# ESP32S31_RADIO register map
Vendor: Espressif; Series: ESP32-S31; File version: 3.52
Registers are 32-bit, read-write, no defined reset value unless marked. A register's access mark holds for its fields unless they carry their own. Offsets are from the block's base; [hi:lo] are bit positions; {n}, {i} and the like mark numbered series.

## PHY_FREQUENCY_CHANNEL_ORACLE — Frequency-memory, hardware channel-switch, NRX and channel-bandwidth registers recovered from complete finite ROM/blob bodies. Names retain UNKNOWN where the instructions prove a field but not its electrical meaning. One physical word has one identity even when a bit has different mode-dependent roles.
Base 0x20100000
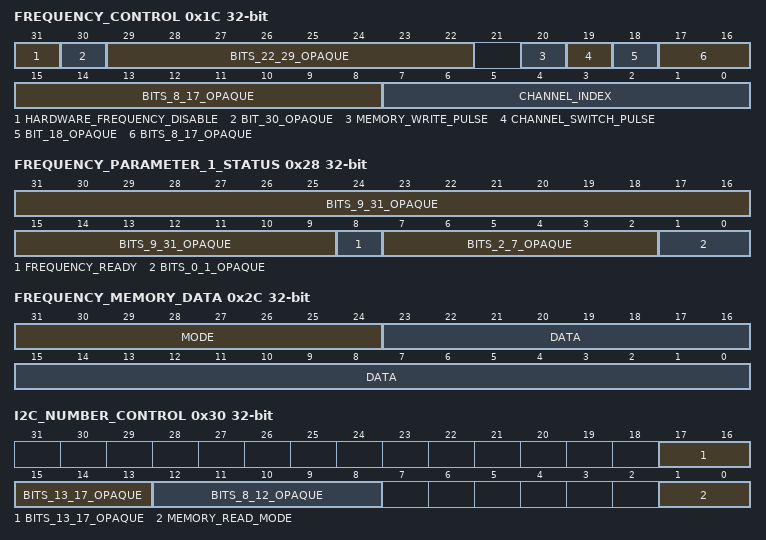
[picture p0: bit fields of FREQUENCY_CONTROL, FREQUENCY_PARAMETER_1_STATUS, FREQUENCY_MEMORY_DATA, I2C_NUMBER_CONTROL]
0x1C FREQUENCY_CONTROL — Project-assigned name. Shared frequency module control word. Bit 18 is both the high bit of an eleven-bit command-memory address and the reset/release bit pulsed by phy_freq_module_resetn.
  [31] HARDWARE_FREQUENCY_DISABLE — Project-assigned name. Complete phy_dis_hw_set_freq sets bit 31 before its two-microsecond delay; complete phy_en_hw_set_freq clears it.
  [30] BIT_30_OPAQUE — Opaque: meaning not established. Complete phy_freq_reg_init sets bit 30.
  [29:22] BITS_22_29_OPAQUE — Opaque: meaning not established. Complete phy_freq_reg_init replaces bits 29:22 with its two input nibbles; the electrical encoding is unknown.
  [20] MEMORY_WRITE_PULSE — Project-assigned name. Complete phy_freq_i2c_mem_write sets then clears bit 20 after publishing data.
  [19] CHANNEL_SWITCH_PULSE — Project-assigned name. Complete phy_freq_chan_en_sw sets bit 19, delays one microsecond, then clears it.
  [18] BIT_18_OPAQUE — Opaque: meaning not established. High address bit during frequency-memory writes; independently cleared then set by complete phy_freq_module_resetn.
  [17:8] BITS_8_17_OPAQUE — Opaque: meaning not established. Low ten bits of the eleven-bit address selected by phy_freq_i2c_mem_write.
  [7:0] CHANNEL_INDEX — Project-assigned name. Complete phy_freq_chan_en_sw replaces the low byte with the caller's frequency-table index.
0x20 FREQUENCY_MEMORY_READ_CONTROL — Project-assigned name. Complete phy_read_rf_freq_mem pulses bit 16 after publishing the address and read mode; all other bits remain preserved and unnamed.
  [16] READ_PULSE — Project-assigned name. Set and then cleared by complete phy_read_rf_freq_mem for one synchronous frequency-memory read transaction.
0x24 WORD_0024_OPAQUE wo — Opaque: meaning not established. Complete phy_freq_reg_init writes the full constant 0x19800249; no constituent electrical fields are public.
  [31:0] BITS_0_31_OPAQUE — Opaque: meaning not established.
0x28 FREQUENCY_PARAMETER_1_STATUS — Project-assigned name. Complete phy_freq_reg_init writes 0x25824e58; phy_bb_init replaces the low baseband-mode field, and the open channel state machine samples bit 8 for the evidenced ready edge.
  [31:9] BITS_9_31_OPAQUE — Opaque: meaning not established. Bits 31:9 of the complete initialization image.
  [8] FREQUENCY_READY ro — Project-assigned name. The complete channel parent samples bit 8 after the frequency-switch delay and branches on its asserted edge.
  [7:2] BITS_2_7_OPAQUE — Opaque: meaning not established. Bits 7:2 of the complete initialization image.
  [1:0] BITS_0_1_OPAQUE — Opaque: meaning not established. Complete phy_bb_init writes encoding two before calibration and zero after the initial channel setup.
0x2C FREQUENCY_MEMORY_DATA wo — Project-assigned name. Data/mode word published by complete phy_freq_i2c_mem_write.
  [31:24] MODE — Project-assigned name.
  [23:0] DATA — Project-assigned name.
0x30 I2C_NUMBER_CONTROL — Project-assigned name. First two five-bit PHY-I2C number addresses packed by complete phy_freq_i2c_num_addr.
  [17:13] BITS_13_17_OPAQUE — Opaque: meaning not established.
  [12:8] BITS_8_12_OPAQUE — Opaque: meaning not established.
  [1:0] MEMORY_READ_MODE — Project-assigned name. Complete phy_read_rf_freq_mem replaces only the low two bits with its read-mode argument.
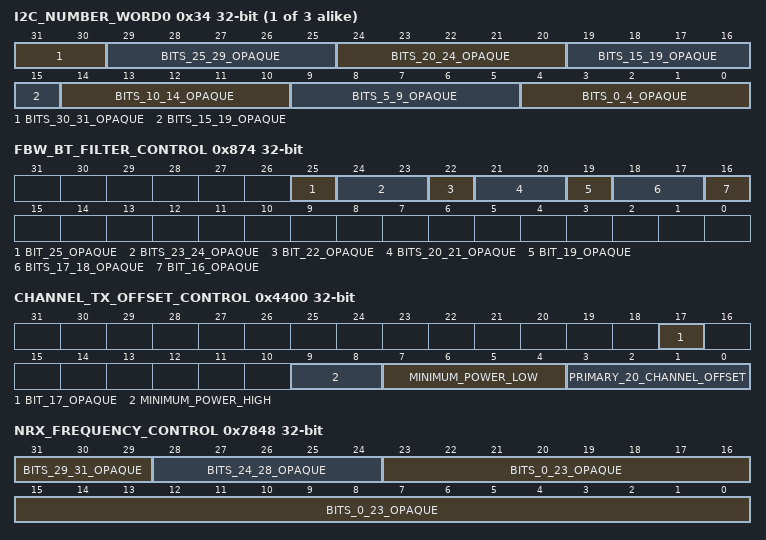
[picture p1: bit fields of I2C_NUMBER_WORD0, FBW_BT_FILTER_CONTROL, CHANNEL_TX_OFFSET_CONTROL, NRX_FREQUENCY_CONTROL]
{0x34+4i} I2C_NUMBER_WORD{i} (i=0..2) wo — Project-assigned name. Six consecutive five-bit PHY-I2C number addresses packed by complete phy_freq_num_get_data; unused slots are zero.
  [31:30] BITS_30_31_OPAQUE — Opaque: meaning not established. High two bits of the complete caller-prepared word; the recovered producer normally leaves them zero.
  [29:25] BITS_25_29_OPAQUE — Opaque: meaning not established.
  [24:20] BITS_20_24_OPAQUE — Opaque: meaning not established.
  [19:15] BITS_15_19_OPAQUE — Opaque: meaning not established.
  [14:10] BITS_10_14_OPAQUE — Opaque: meaning not established.
  [9:5] BITS_5_9_OPAQUE — Opaque: meaning not established.
  [4:0] BITS_0_4_OPAQUE — Opaque: meaning not established.
0x40 FREQUENCY_MEMORY_READ_RESULT ro — Project-assigned name. Complete phy_read_rf_freq_mem returns this full word after the read pulse; individual result fields are interpreted by the caller.
  [31:0] VALUE — Project-assigned name. Complete phy_read_rf_freq_mem returns this full read-only result to its caller.
0x874 FBW_BT_FILTER_CONTROL — Project-assigned name. Shared filter-bandwidth and Bluetooth-filter word independently updated by complete phy_wifi_fbw_sel and phy_bt_filter_reg.
  [25] BIT_25_OPAQUE — Opaque: meaning not established.
  [24:23] BITS_23_24_OPAQUE — Opaque: meaning not established.
  [22] BIT_22_OPAQUE — Opaque: meaning not established.
  [21:20] BITS_20_21_OPAQUE — Opaque: meaning not established.
  [19] BIT_19_OPAQUE — Opaque: meaning not established.
  [18:17] BITS_17_18_OPAQUE — Opaque: meaning not established.
  [16] BIT_16_OPAQUE — Opaque: meaning not established.
0x4400 CHANNEL_TX_OFFSET_CONTROL — Project-assigned name. Canonical multifunction PHY/MAC word. Complete phy_mac_tx_chan_offset and phy_bb_cbw_chan_cfg update the low channel-offset field; complete hal_set_tx_min_pwr updates bits 9:4 and the HE init parent independently sets bit 17.
  [17] BIT_17_OPAQUE — Opaque: meaning not established. The complete HE init parent sets bit 17 through a separate fresh-read RMW.
  [9:8] MINIMUM_POWER_HIGH — Project-assigned name. High two bits of the signed six-bit minimum-power value. Complete hal_set_tx_min_pwr(-11) writes three.
  [7:4] MINIMUM_POWER_LOW — Project-assigned name. Low four bits of the signed six-bit minimum-power value. Complete hal_set_tx_min_pwr(-11) writes five. Complete phy_mac_tx_chan_offset and phy_bb_cbw_chan_cfg preserve this field when updating the adjacent channel offset.
  [3:0] PRIMARY_20_CHANNEL_OFFSET — Project-assigned name.
0x7848 NRX_FREQUENCY_CONTROL — Project-assigned name. NRX initialization and frequency quotient word. Complete phy_nrx_freq_set samples and preserves the high byte and writes a twenty-four-bit quotient. Initialization writes the same complete low twenty-four-bit region with its own image.
  [31:29] BITS_29_31_OPAQUE — Opaque: meaning not established.
  [28:24] BITS_24_28_OPAQUE — Opaque: meaning not established.
  [23:0] BITS_0_23_OPAQUE — Opaque: meaning not established.
0x7CE0 CHANNEL_CBW_CONTROL_0 — Project-assigned name. Complete phy_bb_cbw_chan_cfg replaces the low two-bit CBW-derived field.
  [1:0] BITS_0_1_OPAQUE — Opaque: meaning not established.
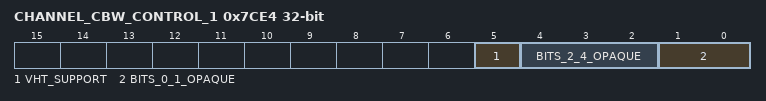
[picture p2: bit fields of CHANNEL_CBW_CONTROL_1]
0x7CE4 CHANNEL_CBW_CONTROL_1 — Project-assigned name. Complete phy_bb_cbw_chan_cfg performs two fresh-read CBW-derived replacements; complete phy_vht_support independently replaces bit five.
  [5] VHT_SUPPORT — Project-assigned name.
  [4:2] BITS_2_4_OPAQUE — Opaque: meaning not established.
  [1:0] BITS_0_1_OPAQUE — Opaque: meaning not established.
